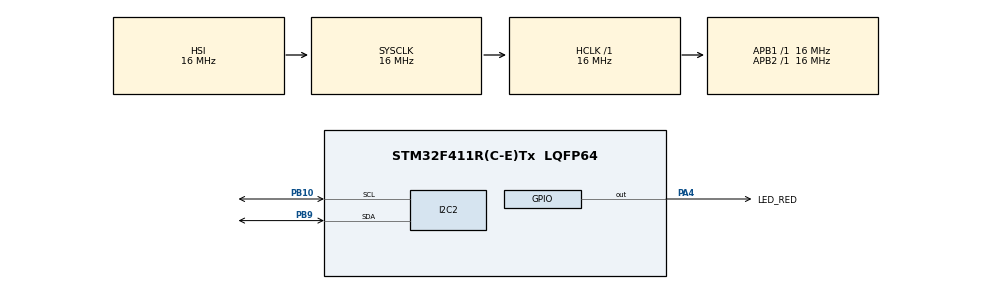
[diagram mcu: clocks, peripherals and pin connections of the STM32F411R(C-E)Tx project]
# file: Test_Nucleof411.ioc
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Mcu.Family=STM32F4
Mcu.Name=STM32F411R(C-E)Tx
Mcu.Package=LQFP64
NVIC.PriorityGroup=NVIC_PRIORITYGROUP_4
PA4.GPIO_Label=LED_RED
PA4.GPIO_PuPd=GPIO_NOPULL
PA4.Signal=GPIO_Output
PB10.Mode=I2C
PB10.Signal=I2C2_SCL
PB9.Mode=I2C
PB9.Signal=I2C2_SDA
PH0\ -\ OSC_IN.Mode=HSE-External-Oscillator
PH0\ -\ OSC_IN.Signal=RCC_OSC_IN
PH1\ -\ OSC_OUT.Mode=HSE-External-Oscillator
PH1\ -\ OSC_OUT.Signal=RCC_OSC_OUT
ProjectManager.HeapSize=0x200
ProjectManager.StackSize=0x400
ProjectManager.TargetToolchain=STM32CubeIDE
RCC.AHBFreq_Value=16000000
RCC.APB1Freq_Value=16000000
RCC.APB2Freq_Value=16000000
RCC.CortexFreq_Value=16000000
RCC.HSE_VALUE=25000000
RCC.HSI_VALUE=16000000
RCC.LSE_VALUE=32768
RCC.SYSCLKFreq_VALUE=16000000
RCC.VCOOutputFreq_Value=192000000
board=custom

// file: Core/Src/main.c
/* USER CODE BEGIN Header */
/**
  ******************************************************************************
  * @file           : main.c
  * @brief          : Main program body
  ******************************************************************************
  * @attention
  *
  * Copyright (c) 2025 STMicroelectronics.
  * All rights reserved.
  *
  * This software is licensed under terms that can be found in the LICENSE file
  * in the root directory of this software component.
  * If no LICENSE file comes with this software, it is provided AS-IS.
  *
  ******************************************************************************
  */
/* USER CODE END Header */
#include "main.h"

I2C_HandleTypeDef hi2c2;

void SystemClock_Config(void);
static void MX_GPIO_Init(void);
static void MX_I2C2_Init(void);

/* USER CODE BEGIN 0 */
int _write(int file,char *ptr, int len){
	int i=0;
	for(i=0;i<len;i++) ITM_SendChar((*ptr++));
	return len;

}

uint8_t count=0;
/* USER CODE END 0 */

int main(void)
{

  /* MCU Configuration--------------------------------------------------------*/

  /* Reset of all peripherals, Initializes the Flash interface and the Systick. */
  HAL_Init();

  /* Configure the system clock */
  SystemClock_Config();

  /* Initialize all configured peripherals */
  MX_GPIO_Init();
  MX_I2C2_Init();

  /* Infinite loop */
  /* USER CODE BEGIN WHILE */
 uint8_t check_eeprom;
 check_eeprom=at24c_Check();
 if(check_eeprom==0){
	 printf("\n\nEEPROM Check Passed");
 }else if((check_eeprom==1)){
	 printf("\n\nEEPROM Check Failed");
 }else{
	 printf("\n\nUnknown error occurred");
 }
  while (1)
  {
	 printf("\n\nNew While Loop");

    /* USER CODE END WHILE */

    /* USER CODE BEGIN 3 */
	  HAL_Delay(1000);
  }
  /* USER CODE END 3 */
}

void SystemClock_Config(void)
{
  RCC_OscInitTypeDef RCC_OscInitStruct = {0};
  RCC_ClkInitTypeDef RCC_ClkInitStruct = {0};

  /** Configure the main internal regulator output voltage
  */
  __HAL_RCC_PWR_CLK_ENABLE();
  __HAL_PWR_VOLTAGESCALING_CONFIG(PWR_REGULATOR_VOLTAGE_SCALE1);

  /** Initializes the RCC Oscillators according to the specified parameters
  * in the RCC_OscInitTypeDef structure.
  */
  RCC_OscInitStruct.OscillatorType = RCC_OSCILLATORTYPE_HSI;
  RCC_OscInitStruct.HSIState = RCC_HSI_ON;
  RCC_OscInitStruct.HSICalibrationValue = RCC_HSICALIBRATION_DEFAULT;
  RCC_OscInitStruct.PLL.PLLState = RCC_PLL_NONE;
  if (HAL_RCC_OscConfig(&RCC_OscInitStruct) != HAL_OK)
  {
    Error_Handler();
  }

  /** Initializes the CPU, AHB and APB buses clocks
  */
  RCC_ClkInitStruct.ClockType = RCC_CLOCKTYPE_HCLK|RCC_CLOCKTYPE_SYSCLK
                              |RCC_CLOCKTYPE_PCLK1|RCC_CLOCKTYPE_PCLK2;
  RCC_ClkInitStruct.SYSCLKSource = RCC_SYSCLKSOURCE_HSI;
  RCC_ClkInitStruct.AHBCLKDivider = RCC_SYSCLK_DIV1;
  RCC_ClkInitStruct.APB1CLKDivider = RCC_HCLK_DIV1;
  RCC_ClkInitStruct.APB2CLKDivider = RCC_HCLK_DIV1;

  if (HAL_RCC_ClockConfig(&RCC_ClkInitStruct, FLASH_LATENCY_0) != HAL_OK)
  {
    Error_Handler();
  }
}

static void MX_I2C2_Init(void)
{

  hi2c2.Instance = I2C2;
  hi2c2.Init.ClockSpeed = 100000;
  hi2c2.Init.DutyCycle = I2C_DUTYCYCLE_2;
  hi2c2.Init.OwnAddress1 = 0;
  hi2c2.Init.AddressingMode = I2C_ADDRESSINGMODE_7BIT;
  hi2c2.Init.DualAddressMode = I2C_DUALADDRESS_DISABLE;
  hi2c2.Init.OwnAddress2 = 0;
  hi2c2.Init.GeneralCallMode = I2C_GENERALCALL_DISABLE;
  hi2c2.Init.NoStretchMode = I2C_NOSTRETCH_DISABLE;
  if (HAL_I2C_Init(&hi2c2) != HAL_OK)
  {
    Error_Handler();
  }

}

static void MX_GPIO_Init(void)
{
  GPIO_InitTypeDef GPIO_InitStruct = {0};

  /* GPIO Ports Clock Enable */
  __HAL_RCC_GPIOH_CLK_ENABLE();
  __HAL_RCC_GPIOA_CLK_ENABLE();
  __HAL_RCC_GPIOB_CLK_ENABLE();

  /*Configure GPIO pin Output Level */
  HAL_GPIO_WritePin(LED_RED_GPIO_Port, LED_RED_Pin, GPIO_PIN_RESET);

  /*Configure GPIO pin : LED_RED_Pin */
  GPIO_InitStruct.Pin = LED_RED_Pin;
  GPIO_InitStruct.Mode = GPIO_MODE_OUTPUT_PP;
  GPIO_InitStruct.Pull = GPIO_NOPULL;
  GPIO_InitStruct.Speed = GPIO_SPEED_FREQ_LOW;
  HAL_GPIO_Init(LED_RED_GPIO_Port, &GPIO_InitStruct);

}

void Error_Handler(void)
{
  __disable_irq();
  while (1)
  {
  }
}
